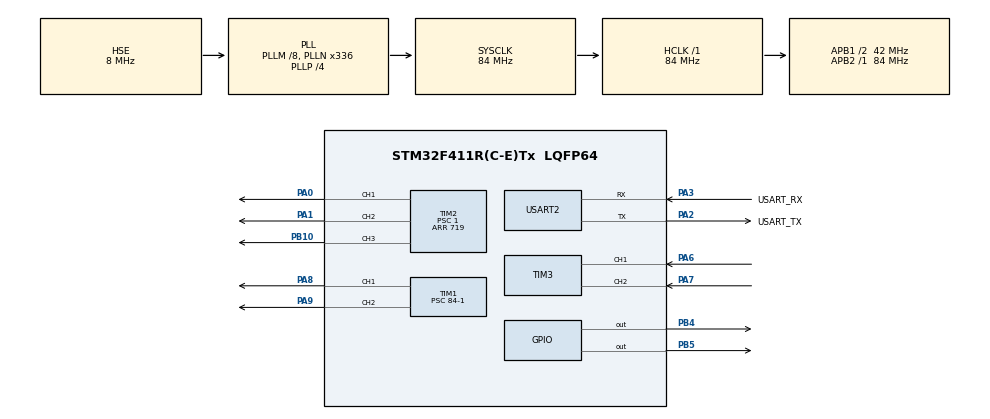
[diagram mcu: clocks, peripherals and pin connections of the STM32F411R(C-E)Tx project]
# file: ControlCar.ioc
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FREERTOS.BinarySemaphores01=myBinarySem01,Dynamic,NULL,Depleted
FREERTOS.Tasks01=ControlTask,0,256,StartDefaultTask,Default,NULL,Dynamic,NULL,NULL;EncoderTask,0,256,StartTask02,Default,NULL,Dynamic,NULL,NULL
FREERTOS.configUSE_NEWLIB_REENTRANT=1
Mcu.Family=STM32F4
Mcu.Name=STM32F411R(C-E)Tx
Mcu.Package=LQFP64
NVIC.PriorityGroup=NVIC_PRIORITYGROUP_4
NVIC.TIM4_IRQn=true\:15\:0\:false\:false\:true\:false\:false\:true\:true
NVIC.TimeBase=TIM4_IRQn
NVIC.TimeBaseIP=TIM4
NVIC.USART2_IRQn=true\:5\:0\:false\:false\:true\:true\:true\:true\:true
PA0-WKUP.GPIO_Speed=GPIO_SPEED_FREQ_HIGH
PA0-WKUP.Signal=S_TIM2_CH1_ETR
PA1.GPIO_Speed=GPIO_SPEED_FREQ_HIGH
PA1.Signal=S_TIM2_CH2
PA13.GPIO_Label=TMS
PA13.Mode=Serial_Wire
PA13.Signal=SYS_JTMS-SWDIO
PA14.GPIO_Label=TCK
PA14.Mode=Serial_Wire
PA14.Signal=SYS_JTCK-SWCLK
PA2.GPIO_Label=USART_TX
PA2.GPIO_Speed=GPIO_SPEED_FREQ_HIGH
PA2.Mode=Asynchronous
PA2.Signal=USART2_TX
PA3.GPIO_Label=USART_RX
PA3.GPIO_PuPd=GPIO_NOPULL
PA3.GPIO_Speed=GPIO_SPEED_FREQ_HIGH
PA3.Mode=Asynchronous
PA3.Signal=USART2_RX
PA6.GPIO_Speed=GPIO_SPEED_FREQ_HIGH
PA6.Signal=S_TIM3_CH1
PA7.GPIO_Speed=GPIO_SPEED_FREQ_HIGH
PA7.Signal=S_TIM3_CH2
PA8.GPIO_Speed=GPIO_SPEED_FREQ_HIGH
PA8.Signal=S_TIM1_CH1
PA9.GPIO_Speed=GPIO_SPEED_FREQ_HIGH
PA9.Signal=S_TIM1_CH2
PB10.GPIO_Speed=GPIO_SPEED_FREQ_HIGH
PB10.Signal=S_TIM2_CH3
PB3.GPIO_Label=SWO
PB3.Signal=SYS_JTDO-SWO
PB4.GPIO_Speed=GPIO_SPEED_FREQ_HIGH
PB4.Signal=GPIO_Output
PB5.GPIO_Speed=GPIO_SPEED_FREQ_HIGH
PB5.Signal=GPIO_Output
PC14-OSC32_IN.Mode=LSE-External-Oscillator
PC14-OSC32_IN.Signal=RCC_OSC32_IN
PC15-OSC32_OUT.Mode=LSE-External-Oscillator
PC15-OSC32_OUT.Signal=RCC_OSC32_OUT
PH0\ -\ OSC_IN.Mode=HSE-External-Clock-Source
PH0\ -\ OSC_IN.Signal=RCC_OSC_IN
PH1\ -\ OSC_OUT.Mode=HSE-External-Clock-Source
PH1\ -\ OSC_OUT.Signal=RCC_OSC_OUT
ProjectManager.HeapSize=0x200
ProjectManager.StackSize=0x400
ProjectManager.TargetToolchain=STM32CubeIDE
RCC.48MHZClocksFreq_Value=84000000
RCC.AHBFreq_Value=84000000
RCC.APB1CLKDivider=RCC_HCLK_DIV2
RCC.APB1Freq_Value=42000000
RCC.APB1TimFreq_Value=84000000
RCC.APB2Freq_Value=84000000
RCC.APB2TimFreq_Value=84000000
RCC.CortexFreq_Value=84000000
RCC.EnbaleCSS=true
RCC.FLatency-AdvancedSettings=FLASH_LATENCY_2
RCC.HCLKFreq_Value=84000000
RCC.HSE_VALUE=8000000
RCC.HSI_VALUE=16000000
RCC.PLLM=8
RCC.PLLN=336
RCC.PLLP=RCC_PLLP_DIV4
RCC.PLLSourceVirtual=RCC_PLLSOURCE_HSE
RCC.SYSCLKFreq_VALUE=84000000
RCC.SYSCLKSource=RCC_SYSCLKSOURCE_PLLCLK
RCC.VCOOutputFreq_Value=336000000
SH.S_TIM1_CH1.0=TIM1_CH1,PWM Generation1 CH1
SH.S_TIM1_CH2.0=TIM1_CH2,PWM Generation2 CH2
SH.S_TIM2_CH1_ETR.0=TIM2_CH1,PWM Generation1 CH1
SH.S_TIM2_CH2.0=TIM2_CH2,PWM Generation2 CH2
SH.S_TIM2_CH3.0=TIM2_CH3,PWM Generation3 CH3
SH.S_TIM3_CH1.0=TIM3_CH1,Encoder_Interface
SH.S_TIM3_CH2.0=TIM3_CH2,Encoder_Interface
TIM1.Channel-PWM\ Generation1\ CH1=TIM_CHANNEL_1
TIM1.Channel-PWM\ Generation2\ CH2=TIM_CHANNEL_2
TIM1.Period=20000-1
TIM1.Prescaler=84-1
TIM2.Channel-PWM\ Generation1\ CH1=TIM_CHANNEL_1
TIM2.Channel-PWM\ Generation2\ CH2=TIM_CHANNEL_2
TIM2.Channel-PWM\ Generation3\ CH3=TIM_CHANNEL_3
TIM2.Period=719
TIM2.Prescaler=1
USART2.VirtualMode=VM_ASYNC
VP_FREERTOS_VS_CMSIS_V1.Mode=CMSIS_V1
VP_SYS_VS_tim4.Mode=TIM4
VP_TIM1_VS_ClockSourceINT.Mode=Internal
VP_TIM2_VS_ClockSourceINT.Mode=Internal
board=NUCLEO-F411RE

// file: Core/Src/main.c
	               /* USER CODE BEGIN Header */
/* USER CODE END Header */
#include "main.h"
#include "cmsis_os.h"

/* Thêm các module tự chia */
#include "motor.h"
#include "servo.h"
#include "encoder.h"
#include "uart_cmd.h"
#include "freertos_tasks.h"

TIM_HandleTypeDef htim1;
TIM_HandleTypeDef htim2;
TIM_HandleTypeDef htim3;
UART_HandleTypeDef huart2;

osThreadId ControlTaskHandle;
osThreadId EncoderTaskHandle;
osSemaphoreId myBinarySem01Handle;

/* USER CODE BEGIN PV */
uint8_t rx_Buffer[RX_BUFFER_SIZE];
volatile uint8_t rx_index = 0;
volatile uint8_t dataComplete = 0;
/* USER CODE END PV */

void SystemClock_Config(void);
static void MX_GPIO_Init(void);
static void MX_TIM1_Init(void);
static void MX_TIM2_Init(void);
static void MX_TIM3_Init(void);
static void MX_USART2_UART_Init(void);

int main(void)
{
  /* MCU Configuration--------------------------------------------------------*/
  HAL_Init();

  /* Configure the system clock */
  SystemClock_Config();

  /* Initialize all configured peripherals */
  MX_GPIO_Init();
  MX_TIM1_Init();
  MX_TIM2_Init();
  MX_TIM3_Init();
  MX_USART2_UART_Init();

  /* Initialize user modules */
  Servo_Init(&htim1);
  Motor_Init(&htim2);
  Encoder_Init(&htim3);

  /* Bắt đầu nhận UART ngắt từng byte */
  HAL_UART_Receive_IT(&huart2, (uint8_t *)&rx_Buffer[rx_index], 1);

  /* Tạo semaphore */
  osSemaphoreDef(myBinarySem01);
  myBinarySem01Handle = osSemaphoreCreate(osSemaphore(myBinarySem01), 1);

  /* Tạo các task */
  osThreadDef(ControlTask, StartControlTask, osPriorityNormal, 0, 256);
  ControlTaskHandle = osThreadCreate(osThread(ControlTask), NULL);

  osThreadDef(EncoderTask, StartEncoderTask, osPriorityNormal, 0, 256);
  EncoderTaskHandle = osThreadCreate(osThread(EncoderTask), NULL);

  /* Bắt đầu scheduler */
  osKernelStart();

  /* Vòng lặp chính - sẽ không chạy tới đây khi FreeRTOS hoạt động */
  while (1)
  {
  }
}

void SystemClock_Config(void)
{
  RCC_OscInitTypeDef RCC_OscInitStruct = {0};
  RCC_ClkInitTypeDef RCC_ClkInitStruct = {0};

  /** Initializes the RCC Oscillators according to the specified parameters
  * in the RCC_OscInitTypeDef structure.
  */
  RCC_OscInitStruct.OscillatorType = RCC_OSCILLATORTYPE_HSE;
  RCC_OscInitStruct.HSEState = RCC_HSE_BYPASS;
  RCC_OscInitStruct.PLL.PLLState = RCC_PLL_ON;
  RCC_OscInitStruct.PLL.PLLSource = RCC_PLLSOURCE_HSE;
  RCC_OscInitStruct.PLL.PLLM = 8;
  RCC_OscInitStruct.PLL.PLLN = 336;
  RCC_OscInitStruct.PLL.PLLP = RCC_PLLP_DIV4;
  RCC_OscInitStruct.PLL.PLLQ = 4;
  if (HAL_RCC_OscConfig(&RCC_OscInitStruct) != HAL_OK)
  {
    Error_Handler();
  }

  /** Initializes the CPU, AHB and APB buses clocks
  */
  RCC_ClkInitStruct.ClockType = RCC_CLOCKTYPE_HCLK|RCC_CLOCKTYPE_SYSCLK
                              |RCC_CLOCKTYPE_PCLK1|RCC_CLOCKTYPE_PCLK2;
  RCC_ClkInitStruct.SYSCLKSource = RCC_SYSCLKSOURCE_PLLCLK;
  RCC_ClkInitStruct.AHBCLKDivider = RCC_SYSCLK_DIV1;
  RCC_ClkInitStruct.APB1CLKDivider = RCC_HCLK_DIV2;
  RCC_ClkInitStruct.APB2CLKDivider = RCC_HCLK_DIV1;

  if (HAL_RCC_ClockConfig(&RCC_ClkInitStruct, FLASH_LATENCY_2) != HAL_OK)
  {
    Error_Handler();
  }
}

static void MX_TIM1_Init(void)
{

  TIM_ClockConfigTypeDef sClockSourceConfig = {0};
  TIM_MasterConfigTypeDef sMasterConfig = {0};
  TIM_OC_InitTypeDef sConfigOC = {0};
  TIM_BreakDeadTimeConfigTypeDef sBreakDeadTimeConfig = {0};

  htim1.Instance = TIM1;
  htim1.Init.Prescaler = 84-1;
  htim1.Init.CounterMode = TIM_COUNTERMODE_UP;
  htim1.Init.Period = 20000-1;
  htim1.Init.ClockDivision = TIM_CLOCKDIVISION_DIV1;
  htim1.Init.RepetitionCounter = 0;
  htim1.Init.AutoReloadPreload = TIM_AUTORELOAD_PRELOAD_DISABLE;
  if (HAL_TIM_Base_Init(&htim1) != HAL_OK)
  {
    Error_Handler();
  }
  sClockSourceConfig.ClockSource = TIM_CLOCKSOURCE_INTERNAL;
  if (HAL_TIM_ConfigClockSource(&htim1, &sClockSourceConfig) != HAL_OK)
  {
    Error_Handler();
  }
  if (HAL_TIM_PWM_Init(&htim1) != HAL_OK)
  {
    Error_Handler();
  }
  sMasterConfig.MasterOutputTrigger = TIM_TRGO_RESET;
  sMasterConfig.MasterSlaveMode = TIM_MASTERSLAVEMODE_DISABLE;
  if (HAL_TIMEx_MasterConfigSynchronization(&htim1, &sMasterConfig) != HAL_OK)
  {
    Error_Handler();
  }
  sConfigOC.OCMode = TIM_OCMODE_PWM1;
  sConfigOC.Pulse = 0;
  sConfigOC.OCPolarity = TIM_OCPOLARITY_HIGH;
  sConfigOC.OCNPolarity = TIM_OCNPOLARITY_HIGH;
  sConfigOC.OCFastMode = TIM_OCFAST_DISABLE;
  sConfigOC.OCIdleState = TIM_OCIDLESTATE_RESET;
  sConfigOC.OCNIdleState = TIM_OCNIDLESTATE_RESET;
  if (HAL_TIM_PWM_ConfigChannel(&htim1, &sConfigOC, TIM_CHANNEL_1) != HAL_OK)
  {
    Error_Handler();
  }
  if (HAL_TIM_PWM_ConfigChannel(&htim1, &sConfigOC, TIM_CHANNEL_2) != HAL_OK)
  {
    Error_Handler();
  }
  sBreakDeadTimeConfig.OffStateRunMode = TIM_OSSR_DISABLE;
  sBreakDeadTimeConfig.OffStateIDLEMode = TIM_OSSI_DISABLE;
  sBreakDeadTimeConfig.LockLevel = TIM_LOCKLEVEL_OFF;
  sBreakDeadTimeConfig.DeadTime = 0;
  sBreakDeadTimeConfig.BreakState = TIM_BREAK_DISABLE;
  sBreakDeadTimeConfig.BreakPolarity = TIM_BREAKPOLARITY_HIGH;
  sBreakDeadTimeConfig.AutomaticOutput = TIM_AUTOMATICOUTPUT_DISABLE;
  if (HAL_TIMEx_ConfigBreakDeadTime(&htim1, &sBreakDeadTimeConfig) != HAL_OK)
  {
    Error_Handler();
  }
  HAL_TIM_MspPostInit(&htim1);

}

static void MX_TIM2_Init(void)
{

  TIM_ClockConfigTypeDef sClockSourceConfig = {0};
  TIM_MasterConfigTypeDef sMasterConfig = {0};
  TIM_OC_InitTypeDef sConfigOC = {0};

  htim2.Instance = TIM2;
  htim2.Init.Prescaler = 1;
  htim2.Init.CounterMode = TIM_COUNTERMODE_UP;
  htim2.Init.Period = 719;
  htim2.Init.ClockDivision = TIM_CLOCKDIVISION_DIV1;
  htim2.Init.AutoReloadPreload = TIM_AUTORELOAD_PRELOAD_DISABLE;
  if (HAL_TIM_Base_Init(&htim2) != HAL_OK)
  {
    Error_Handler();
  }
  sClockSourceConfig.ClockSource = TIM_CLOCKSOURCE_INTERNAL;
  if (HAL_TIM_ConfigClockSource(&htim2, &sClockSourceConfig) != HAL_OK)
  {
    Error_Handler();
  }
  if (HAL_TIM_PWM_Init(&htim2) != HAL_OK)
  {
    Error_Handler();
  }
  sMasterConfig.MasterOutputTrigger = TIM_TRGO_RESET;
  sMasterConfig.MasterSlaveMode = TIM_MASTERSLAVEMODE_DISABLE;
  if (HAL_TIMEx_MasterConfigSynchronization(&htim2, &sMasterConfig) != HAL_OK)
  {
    Error_Handler();
  }
  sConfigOC.OCMode = TIM_OCMODE_PWM1;
  sConfigOC.Pulse = 0;
  sConfigOC.OCPolarity = TIM_OCPOLARITY_HIGH;
  sConfigOC.OCFastMode = TIM_OCFAST_DISABLE;
  if (HAL_TIM_PWM_ConfigChannel(&htim2, &sConfigOC, TIM_CHANNEL_1) != HAL_OK)
  {
    Error_Handler();
  }
  if (HAL_TIM_PWM_ConfigChannel(&htim2, &sConfigOC, TIM_CHANNEL_2) != HAL_OK)
  {
    Error_Handler();
  }
  if (HAL_TIM_PWM_ConfigChannel(&htim2, &sConfigOC, TIM_CHANNEL_3) != HAL_OK)
  {
    Error_Handler();
  }
  HAL_TIM_MspPostInit(&htim2);

}

static void MX_TIM3_Init(void)
{

  TIM_Encoder_InitTypeDef sConfig = {0};
  TIM_MasterConfigTypeDef sMasterConfig = {0};

  htim3.Instance = TIM3;
  htim3.Init.Prescaler = 0;
  htim3.Init.CounterMode = TIM_COUNTERMODE_UP;
  htim3.Init.Period = 65535;
  htim3.Init.ClockDivision = TIM_CLOCKDIVISION_DIV1;
  htim3.Init.AutoReloadPreload = TIM_AUTORELOAD_PRELOAD_DISABLE;
  sConfig.EncoderMode = TIM_ENCODERMODE_TI12;
  sConfig.IC1Polarity = TIM_ICPOLARITY_FALLING;
  sConfig.IC1Selection = TIM_ICSELECTION_DIRECTTI;
  sConfig.IC1Prescaler = TIM_ICPSC_DIV1;
  sConfig.IC1Filter = 0;
  sConfig.IC2Polarity = TIM_ICPOLARITY_FALLING;
  sConfig.IC2Selection = TIM_ICSELECTION_DIRECTTI;
  sConfig.IC2Prescaler = TIM_ICPSC_DIV1;
  sConfig.IC2Filter = 0;
  if (HAL_TIM_Encoder_Init(&htim3, &sConfig) != HAL_OK)
  {
    Error_Handler();
  }
  sMasterConfig.MasterOutputTrigger = TIM_TRGO_RESET;
  sMasterConfig.MasterSlaveMode = TIM_MASTERSLAVEMODE_DISABLE;
  if (HAL_TIMEx_MasterConfigSynchronization(&htim3, &sMasterConfig) != HAL_OK)
  {
    Error_Handler();
  }

}

static void MX_USART2_UART_Init(void)
{

  huart2.Instance = USART2;
  huart2.Init.BaudRate = 115200;
  huart2.Init.WordLength = UART_WORDLENGTH_8B;
  huart2.Init.StopBits = UART_STOPBITS_1;
  huart2.Init.Parity = UART_PARITY_NONE;
  huart2.Init.Mode = UART_MODE_TX_RX;
  huart2.Init.HwFlowCtl = UART_HWCONTROL_NONE;
  huart2.Init.OverSampling = UART_OVERSAMPLING_16;
  if (HAL_UART_Init(&huart2) != HAL_OK)
  {
    Error_Handler();
  }

}

static void MX_GPIO_Init(void)
{
  GPIO_InitTypeDef GPIO_InitStruct = {0};

  /* GPIO Ports Clock Enable */
  __HAL_RCC_GPIOC_CLK_ENABLE();
  __HAL_RCC_GPIOD_CLK_ENABLE();
  __HAL_RCC_GPIOA_CLK_ENABLE();
  __HAL_RCC_GPIOB_CLK_ENABLE();

  /*Configure GPIO pin Output Level */
  HAL_GPIO_WritePin(GPIOB, GPIO_PIN_4|GPIO_PIN_5, GPIO_PIN_RESET);

  /*Configure GPIO pins : PB4 PB5 */
  GPIO_InitStruct.Pin = GPIO_PIN_4|GPIO_PIN_5;
  GPIO_InitStruct.Mode = GPIO_MODE_OUTPUT_PP;
  GPIO_InitStruct.Pull = GPIO_NOPULL;
  GPIO_InitStruct.Speed = GPIO_SPEED_FREQ_HIGH;
  HAL_GPIO_Init(GPIOB, &GPIO_InitStruct);

}

void HAL_UART_RxCpltCallback(UART_HandleTypeDef *huart)
{
  if (huart->Instance == USART2)
  {
    if (rx_Buffer[rx_index] == ' ')
    {
      rx_Buffer[rx_index] = '\0';
      dataComplete = 1;
      osSemaphoreRelease(myBinarySem01Handle);
    }
    else
    {
      rx_index++;
      HAL_UART_Receive_IT(&huart2, (uint8_t *)&rx_Buffer[rx_index], 1);
    }
  }
}

void HAL_TIM_PeriodElapsedCallback(TIM_HandleTypeDef *htim)
{
  if (htim->Instance == TIM4) {
    HAL_IncTick();
  }
}

void Error_Handler(void)
{
  while (1)
  {
    // Treo tại đây để debug khi có lỗi
  }
}
